# Musca_B1 register map
Vendor: ARM Ltd.; Series: ARMv8-M Mainline; File version: 1.0
CPU: CM33 r0p2, little endian, MPU, FPU, 4 interrupt priority bits, 8 SAU regions
Registers are 32-bit, read-write, reset 0x0 unless marked. A register's access mark holds for its fields unless they carry their own. Offsets are from the block's base; [hi:lo] are bit positions; {n}, {i} and the like mark numbered series.

## iCache — Cache
Base 0x50010000
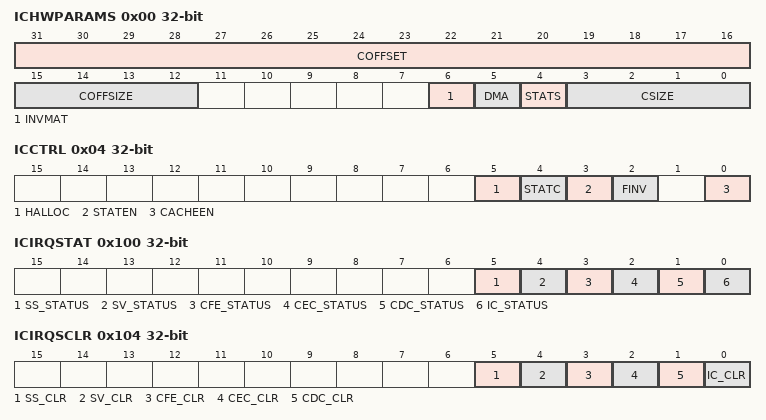
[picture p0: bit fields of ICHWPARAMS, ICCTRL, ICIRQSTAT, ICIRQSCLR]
0x00 ICHWPARAMS ro — Hardware Parameter Register
  [31:16] COFFSET — Cacheable Offset Address
  [15:12] COFFSIZE — Cacheable Block Size
  [6] INVMAT — Indicates whether invalidate cache line on write match is enabled
    1=Enabled (Indicates Invalidate Cache Line on Write Match is enabled)
  [5] DMA — Presence of DMA Engine
    1=Support (The Instruction cache supports pre-fetch and locking); 0=Unsupport (The Instruction cache does not support pre-fetch and locking)
  [4] STATS — Presence of Statistic Functionality
  [3:0] CSIZE — Cache size: Defines the size of the instruction cache
0x04 ICCTRL — Instruction Cache Control Register
  [5] HALLOC — Enable Handler Allocation
    0=LOW (All incoming handler code fetches are not allocated a cache line if a miss occurs); 1=HIGH (Handler code access is treated like any other code access arriving at its interface)
  [4] STATC wo — Clear Statistic values
    1=Clear (Triggers the instruction cache to start clear all cache statistic counters)
  [3] STATEN — Enable Statistic function
    1=Enabled (Cache statistic counters are enabled); 0=Disabled (Cache statistic counters are disabled)
  [2] FINV wo — Full Cache Invalidate
    1=Invalidate (Triggers the instruction cache to start invalidating all cache lines)
  [0] CACHEEN — Enable Cache
    1=Enabled (Caching is enabled); 0=Disabled (All accesses bypass the cache)
0x100 ICIRQSTAT ro — Interrupt Request Status Register
  [5] SS_STATUS — Statistics Saturated Status
    1=Saturated (Indicates that the internal statistic counters have saturated)
  [4] SV_STATUS — Security violation IRQ Status
  [3] CFE_STATUS — Cache Fill Error IRQ Status
    1=Err_Occurred (Indicates that a bus error occurred while filling a cache line)
  [2] CEC_STATUS — Cache Enable Complete IRQ Status
    1=Completed (Indicates that a request to enable the cache has been completed)
  [1] CDC_STATUS — Cache Disable Complete IRQ Status
    1=Completed (Indicates that a request to disable the cache has been completed)
  [0] IC_STATUS — Invalidate Complete IRQ Status
    1=Completed (Indicates that a cache invalidation process has been completed)
0x104 ICIRQSCLR wo — Interrupt Status Clear register
  [5] SS_CLR — Statistics Saturated Status Clear
    1=Clear the Statistics Saturated Status
  [4] SV_CLR — Security violation IRQ Status Clear
    1=Clear the Security violation IRQ Status
  [3] CFE_CLR — Cache Fill Error IRQ Status Clear
    1=Clear the Cache Fill Error IRQ Status
  [2] CEC_CLR — Cache Enable Complete IRQ Status Clear
    1=Clear the Cache Enable Complete IRQ Status
  [1] CDC_CLR — Cache Disable Complete IRQ Status Clear
    1=Clear Cache Disable Complete IRQ Status
  [0] IC_CLR — Invalidate Complete IRQ Status Clear
    1=Clear the Invalidate Complete IRQ Status
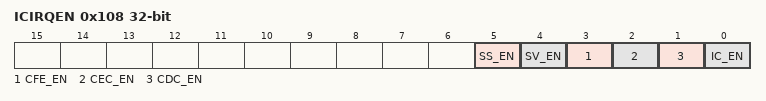
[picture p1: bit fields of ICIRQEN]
0x108 ICIRQEN — Interrupt Enable register
  [5] SS_EN — Statistics Saturated Enable
    1=Enabled (Enable the Statistics Saturated); 0=Disabled (Disable the Statistics Saturated)
  [4] SV_EN — Security violation IRQ Enable
    1=Enabled (Enable the Security violation IRQ); 0=Disabled (Disable the Security violation IRQ)
  [3] CFE_EN — Cache Fill Error IRQ Enable
    1=Enabled (Enable the Cache Fill Error IRQ); 0=Disabled (Disable the Cache Fill Error IRQ)
  [2] CEC_EN — Cache Enable Complete IRQ Enable
    1=Enabled (Enable the Cache Enable Complete IRQ); 0=Disabled (Disable the Cache Enable Complete IRQ)
  [1] CDC_EN — Cache Disable Complete IRQ Enable
    1=Enabled (Enable the Cache Disable Complete IRQ); 0=Disabled (Disable the Cache Disable Complete IRQ)
  [0] IC_EN — Invalidate Complete IRQ Enable
    1=Enabled (Enable the Invalidate Complete IRQ); 0=Disabled (Disable the Invalidate Complete IRQ)
0x10C ICDBGFILLERR ro — Address where the latest fill error was seen
0x300 ICSH ro — Instruction Cache Statistic Hit Count register
0x304 ICSM ro — Instruction Cache Statistic Miss Count register
0x308 ICSUC ro — Instruction Cache Statistic Uncached Count register
0xFD0 PIDR4 ro reset 0x4 — Product ID Register 4
{0xFC0+4i} PIDR{i} ro (i=5..7) — Product ID Register {i}
0xFE0 PIDR0 ro reset 0x57 — Product ID Register 0
0xFE4 PIDR1 ro reset 0xB8 — Product ID Register 1
0xFE8 PIDR2 ro reset 0xB — Product ID Register 2
0xFEC PIDR3 ro — Product ID Register 3
0xFF0 CIDR0 ro reset 0xD — Component ID Register 0
0xFF4 CIDR1 ro reset 0xF0 — Component ID Register 1
0xFF8 CIDR2 ro reset 0x5 — Component ID Register 2
0xFFC CIDR3 ro reset 0xB1 — Component ID Register 3
